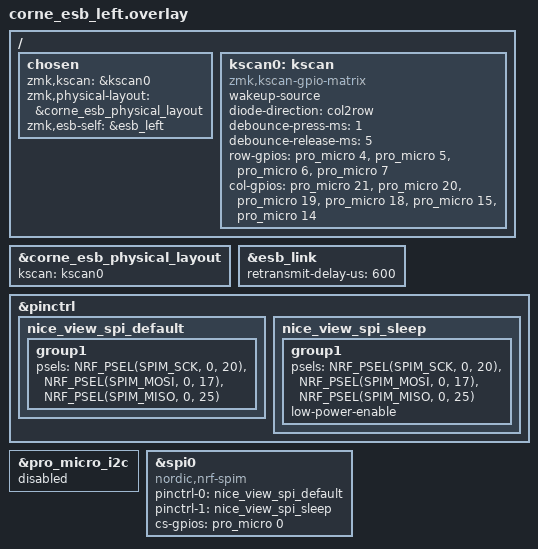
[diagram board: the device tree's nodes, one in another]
#include "corne_esb_matrix.dtsi"
#include "corne_esb_addr.dtsi"

/ {
    chosen {
        zmk,kscan = &kscan0;
        zmk,physical-layout = &corne_esb_physical_layout;
        zmk,esb-self = &esb_left;
    };

    /* Standard corne (crkbd) pinout, same debounce as the old corne-lp BLE
     * config. */
    kscan0: kscan {
        compatible = "zmk,kscan-gpio-matrix";
        wakeup-source;
        diode-direction = "col2row";
        debounce-press-ms = <1>;
        debounce-release-ms = <5>;
        row-gpios
            = <&pro_micro 4 (GPIO_ACTIVE_HIGH | GPIO_PULL_DOWN)>
            , <&pro_micro 5 (GPIO_ACTIVE_HIGH | GPIO_PULL_DOWN)>
            , <&pro_micro 6 (GPIO_ACTIVE_HIGH | GPIO_PULL_DOWN)>
            , <&pro_micro 7 (GPIO_ACTIVE_HIGH | GPIO_PULL_DOWN)>
            ;
        col-gpios
            = <&pro_micro 21 GPIO_ACTIVE_HIGH>
            , <&pro_micro 20 GPIO_ACTIVE_HIGH>
            , <&pro_micro 19 GPIO_ACTIVE_HIGH>
            , <&pro_micro 18 GPIO_ACTIVE_HIGH>
            , <&pro_micro 15 GPIO_ACTIVE_HIGH>
            , <&pro_micro 14 GPIO_ACTIVE_HIGH>
            ;
    };
};

&corne_esb_physical_layout {
    kscan = <&kscan0>;
};

&esb_link {
    retransmit-delay-us = <600>;
};

/* nice!view display bus.
 *
 * The panel plugs into the pro_micro header and is wired for SCK on the D3 pad
 * (P0.20) and MOSI on the D2 pad (P0.17) — the pinout the stock nice_view_adapter
 * targets. The board's `pro_micro_spi` is spi1 (SCK P1.13, MOSI P0.10), which
 * never reaches the panel and leaves it showing "no-signal" static, so drive the
 * display on spi0 remapped onto the correct pads instead. CS is on the D0 pad
 * (pro_micro 0). spi0 and pro_micro_i2c share nRF SERIAL0, so the I2C alias is
 * disabled here. The stock `nice_view` shield (build.yaml) adds the ls0xx panel
 * on &nice_view_spi. */
&pinctrl {
    nice_view_spi_default: nice_view_spi_default {
        group1 {
            psels = <NRF_PSEL(SPIM_SCK, 0, 20)>,
                    <NRF_PSEL(SPIM_MOSI, 0, 17)>,
                    <NRF_PSEL(SPIM_MISO, 0, 25)>;
        };
    };
    nice_view_spi_sleep: nice_view_spi_sleep {
        group1 {
            psels = <NRF_PSEL(SPIM_SCK, 0, 20)>,
                    <NRF_PSEL(SPIM_MOSI, 0, 17)>,
                    <NRF_PSEL(SPIM_MISO, 0, 25)>;
            low-power-enable;
        };
    };
};

&pro_micro_i2c {
    status = "disabled";
};

nice_view_spi: &spi0 {
    compatible = "nordic,nrf-spim";
    status = "okay";
    pinctrl-0 = <&nice_view_spi_default>;
    pinctrl-1 = <&nice_view_spi_sleep>;
    pinctrl-names = "default", "sleep";
    cs-gpios = <&pro_micro 0 GPIO_ACTIVE_HIGH>;
};
